# STM32MP13xx register map
File version: 1.7
CPU: CA7 r0p0, little endian, MPU, FPU, 4 interrupt priority bits
Registers are 32-bit, read-write, reset 0x0 unless marked. A register's access mark holds for its fields unless they carry their own. Offsets are from the block's base; [hi:lo] are bit positions; {n}, {i} and the like mark numbered series.

## BSEC
Base 0x5C005000
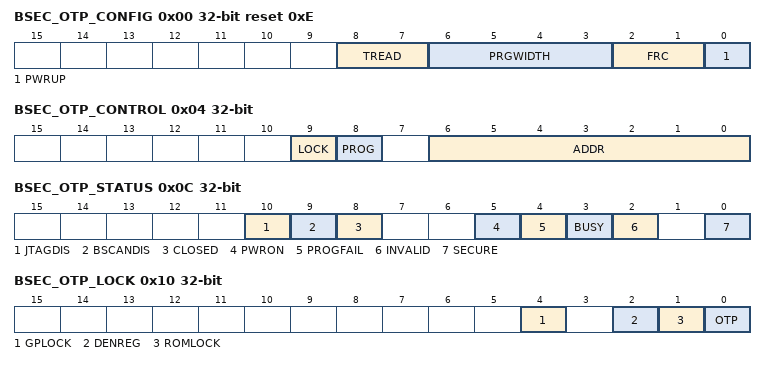
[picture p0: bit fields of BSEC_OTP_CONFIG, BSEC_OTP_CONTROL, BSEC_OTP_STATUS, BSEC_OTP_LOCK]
0x00 BSEC_OTP_CONFIG reset 0xE — BSEC OTP configuration register
  [8:7] TREAD — set OTP reading current level (default = 0b00)
  [6:3] PRGWIDTH — OTP programming pulse width (default = 0b0001)
  [2:1] FRC — OTP clock frequency range selection Note: 0b11 is used by default. OTP initial read is always using an internal OSC with 64 MHz max frequency. Reading OTP at a lower frequency than the range programmed by FRC[1:0] is possible.
    0=10 MHz less than or equal to frequency less than or equal to 20 MHz; 1=20 MHz less than or equal to frequency less than or equal to 30 MHz; 2=30 MHz less than or equal to frequency less than or equal to 45 MHz; 3=45 MHz less than or equal to frequency less than or equal to 67 MHz
  [0] PWRUP — OTP power-up control Note: After the power-on initial read of OTP, BSEC powers down OTP. PWRUP bit is then cleared. Prior to any read or programming operation, OTP must be powered up again by setting PWRUP bit. OTP read is qualified by pwrok input signal, which indicates that VDD and VDD1 supplies are in valid range.
    0=OTP powered down; 1=OTP powered up
0x04 BSEC_OTP_CONTROL
  [9] LOCK — OTP permanent word lock control
    0=OTP normal word programing; 1=OTP permanent write lock word programming
  [8] PROG — OTP operation control
    0=OTP read operation; 1=OTP program operation
  [6:0] ADDR — OTP word address Actual OTP word address. Words address are from 0 to 95 for BSEC Note: the actual OTP word address is adjusted according to the redundancy or ECC scheme.
0x08 BSEC_OTP_WRDATA — BSEC OTP write data register
  [31:0] WRDATA — OTP write data
0x0C BSEC_OTP_STATUS ro
  [10] JTAGDIS — JTAG port status
    0=JTAG Port is not disabled; 1=JTAG Port is disabled except for accessing REV_ID information (see 'Device electronic signature' section) and BSEC_JTAGIN register
  [9] BSCANDIS — Boundary Scan status
    0=Boundary Scan is not disabled; 1=Boundary Scan is disabled
  [8] CLOSED — OTP_SECURED mode
    0=OTP-SECURED open device; 1=OTP-SECURED closed device
  [5] PWRON — OTP power status Note: used to poll pwrok signal value
    0=OTP in power off; 1=OTP in power on
  [4] PROGFAIL — last programming status
    0=OTP successful last programming; 1=OTP failed last programming
  [3] BUSY — OTP operation status Note: bit polling is used to determine operation completion.
    0=OTP idle; 1=OTP operation on going
  [2] INVALID — OTP invalid mode
    0=OTP mode is not OTP-INVALID; 1=OTP mode is OTP-INVALID
  [0] SECURE — OTP secured mode
    0=OTP mode is not OTP-SECURED; 1=OTP mode is OTP-SECURED
0x10 BSEC_OTP_LOCK — BSEC OTP lock configuration register
  [4] GPLOCK — programming sticky lock
    0=programming allowed; 1=programming disabled until next system reset
  [2] DENREG — debug enable register sticky lock
    0=BSEC_DENABLE register not locked; 1=BSEC_DENABLE register locked until next system reset
  [1] ROMLOCK — Upper ROM region read lock The upper ROM region is accessible only in OTP-SECURED open and OTP-SECURED closed modes and ROMLOCK bit is relevant only in these modes.
    0=Upper ROM region is accessible; 1=Upper ROM region is no more accessible until next system reset
  [0] OTP — upper OTP read lock
    0=upper OTP not locked; 1=upper OTP cannot be reloaded until next system reset
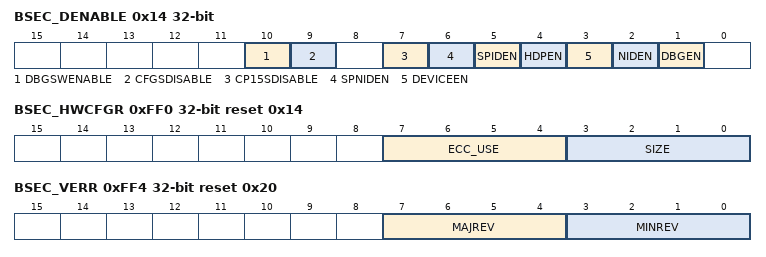
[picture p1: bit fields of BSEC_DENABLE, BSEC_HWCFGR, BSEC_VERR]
0x14 BSEC_DENABLE — BSEC debug configuration register
  [10] DBGSWENABLE — control self hosted debug enable with signal dbgswenable
    0=Software access to all debug components is disabled; 1=Software access to all debug components is enabled
  [9] CFGSDISABLE — write access to secure GIC registers disable with signal cfgsdisable
    0=no effect, all GIC registers are accessible; 1=Disable write access to some secure GIC registers
  [7] CP15SDISABLE — write access to some secure Cortex-A7 CP15 registers disable
    0=All CP15 registers are accessible; 1=Disable write access to some secure CP15 registers into Cortex-A7 corresponding CPU
  [6] SPNIDEN — secure privilege non-invasive debug enable with signal spiden
    0=secure privilege non-invasive debug disabled; 1=secure privilege non-invasive debug enabled
  [5] SPIDEN — secure privilege invasive debug enable with signal spniden
    0=secure privilege invasive debug disabled; 1=secure privilege invasive debug enabled
  [4] HDPEN — hardware debug port enable with signal hdpen
    0=hardware debug port disabled; 1=hardware debug port enabled
  [3] DEVICEEN — controls access to debug component via external debug port by signal deviceen
    0=disabled; 1=enabled
  [2] NIDEN — non-invasive debug enable with signal niden
    0=non-invasive debug disabled; 1=non-invasive debug enabled
  [1] DBGEN — debug enable with signal dbgen
    0=disabled; 1=enabled
{0x1C+4i} BSEC_OTP_DISTURBED{i} ro (i=0..2) — BSEC OTP disturbed status register {i}
  [31:0] DIS — disturbed status of the corresponding OTP word Note: ECC bits resilience against hardware attacks is applied only to lower OTP region.
    0=OTP word has been read correctly; 1=OTP word is disturbed, either because of a read with disturbcheck failed or because the spare ECC bits [37:32] for words 0 to 31 do not match expected value. It may result from a possible hardware attack.
{0x34+4i} BSEC_OTP_ERROR{i} ro (i=0..2) — BSEC OTP error status register {i}
  [31:0] ERR — error status of the correspond OTP word
    0=OTP word has been read correctly; 1=OTP word is erroneous, either because 2:1 redundancy has failed for words 0 to 31 or because ECC check has failed for words 32 to 95
{0x4C+4i} BSEC_OTP_WRLOCK{i} ro (i=0..2) — BSEC OTP lock status register {i}
  [31:0] WRLOCK — permanent word lock status of the correspond OTP word
    0=OTP word not locked; 1=OTP word permanently locked
{0x64+4i} BSEC_OTP_SPLOCK{i} (i=0..2) — BSEC OTP sticky programming lock register {i}
  [31:0] SPLOCK — lock programming for the OTP word until next power-on reset
    0=OTP word not locked; 1=OTP word locked for programming
{0x7C+4i} BSEC_OTP_SWLOCK{i} reset 0x1 (i=0..2) — BSEC OTP shadow write sticky lock register {i}
  [31:0] SWLOCK — lock the writing for the OTP shadow word until next power-on reset. Note: BSEC_OTP_SWLOCK0 bit 0 is forced to 1 by hardware, writing to this bit has no effect.
    0=shadow word not locked; 1=shadow word locked and cannot be written by software
{0x94+4i} BSEC_OTP_SRLOCK{i} (reset mask 0xFFFFFFF0) (i=0..2) — BSEC OTP shadow read sticky lock register {i}
  [31:0] SRLOCK — prevent reloading of the shadow word from OTP until next power-on reset. Note: Reloading of OTP word 0 is prevented after its initial read on a system reset.
    0=OTP word not locked; 1=OTP word locked and cannot be reloaded
0xAC BSEC_JTAGIN ro — BSEC JTAG input register
  [31:0] DATA — JTAG input data 32-bit copy from JTAG SoC register
0xB0 BSEC_JTAGOUT ro — BSEC JTAG output register
  [31:0] DATA — JTAG output data 32-bit copy to JTAG SoC register
0xB4 BSEC_SCRATCH
  [31:0] DATA — scratch data This register is a general purpose register.
{0x200+4i} BSEC_OTP_DATA{i} reset not defined (i=0..95) — BSEC shadow register {i}
  [31:0] DATA — shadow register read from OTP or written by software (OTP emulation mode) The update of shadow registers is controlled by other registers and by OTP security mode.
0xFF0 BSEC_HWCFGR ro reset 0x14 — BSEC hardware configuration register
  [7:4] ECC_USE — protection / redundancy scheme used Others: reserved
    0=No; 1=ECC for upper OTP bits used
  [3:0] SIZE — OTP block size Others: reserved
    2=2 Kbits; 4=4 Kbits; 8=8 Kbits
0xFF4 BSEC_VERR ro reset 0x20 — BSEC version register
  [7:4] MAJREV — major revision information
  [3:0] MINREV — minor revision information
0xFF8 BSEC_IPIDR ro reset 0x100032 — BSEC identification register
  [31:0] ID — BSEC identification
0xFFC BSEC_SIDR ro reset 0xA3C5DD04 — BSEC size identification register
  [31:0] SID — BSEC size identification
